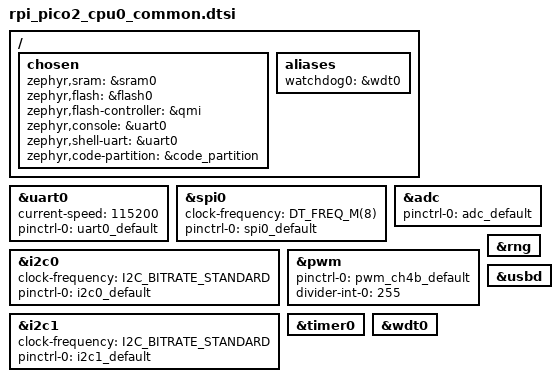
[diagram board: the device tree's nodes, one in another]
/*
 * Copyright (c) Qualcomm Technologies, Inc. and/or its subsidiaries.
 *
 * SPDX-License-Identifier: Apache-2.0
 */

#include <freq.h>

#include <zephyr/dt-bindings/i2c/i2c.h>
#include <zephyr/dt-bindings/pwm/pwm.h>
#include <raspberrypi/partitions_0x0_default.dtsi>

#include "rpi_pico2_common.dtsi"

/ {
	chosen {
		zephyr,sram = &sram0;
		zephyr,flash = &flash0;
		zephyr,flash-controller = &qmi;
		zephyr,console = &uart0;
		zephyr,shell-uart = &uart0;
		zephyr,code-partition = &code_partition;
	};

	aliases {
		watchdog0 = &wdt0;
	};
};

&uart0 {
	current-speed = <115200>;
	status = "okay";
	pinctrl-0 = <&uart0_default>;
	pinctrl-names = "default";
};

&spi0 {
	clock-frequency = <DT_FREQ_M(8)>;
	pinctrl-0 = <&spi0_default>;
	pinctrl-names = "default";
};

&i2c0 {
	clock-frequency = <I2C_BITRATE_STANDARD>;
	pinctrl-0 = <&i2c0_default>;
	pinctrl-names = "default";
	status = "okay";
};

&i2c1 {
	clock-frequency = <I2C_BITRATE_STANDARD>;
	pinctrl-0 = <&i2c1_default>;
	pinctrl-names = "default";
	status = "okay";
};

&adc {
	pinctrl-0 = <&adc_default>;
	pinctrl-names = "default";
	status = "okay";
};

&pwm {
	pinctrl-0 = <&pwm_ch4b_default>;
	pinctrl-names = "default";
	divider-int-0 = <255>;
};

&timer0 {
	status = "okay";
};

&wdt0 {
	status = "okay";
};

&rng {
	status = "okay";
};

zephyr_udc0: &usbd {
	status = "okay";
};
